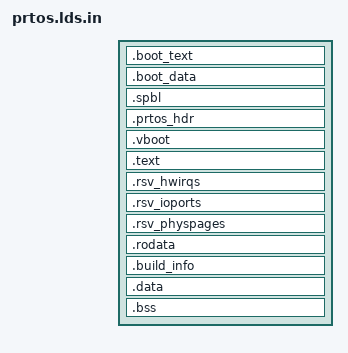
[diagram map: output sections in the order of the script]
/*
 * FILE: prtos.lds
 *
 * ld script to build the aarch64 version
 *
 * www.prtos.org
 */

#include <config.h>

OUTPUT_FORMAT("elf64-littleaarch64", "elf64-bigaarch64", "elf64-littleaarch64")
OUTPUT_ARCH("aarch64")
ENTRY(start)

PHYSOFFSET = - CONFIG_PRTOS_OFFSET + CONFIG_PRTOS_LOAD_ADDR;

SECTIONS
{
    . = CONFIG_PRTOS_OFFSET;
    _sprtos = .;

    _sboot = . + PHYSOFFSET;
    .boot_text ALIGN(0x1000) :  AT (ADDR (.boot_text) + PHYSOFFSET) {
        _stext = .;
        *(.boot.text)
        _etext = .;

        _idmap_start = .;
        *(.boot.text.header)
        *(.boot.text.idmap)
        *(.boot.rodata.idmap)
        *(.boot.data.idmap)
        _idmap_end = .;
    }
    .boot_data : AT (ADDR (.boot_data) + PHYSOFFSET) {
        *(.boot.data)
    }
    _eboot = . + PHYSOFFSET;


    .spbl ALIGN(0x1000) :  AT (ADDR (.spbl) + PHYSOFFSET) {
        _spbl = .;
        *(.pbl)
        _epbl = .;
    }
    .prtos_hdr ALIGN(0x1000) :  AT (ADDR (.prtos_hdr) + PHYSOFFSET) {
        *(.prtos_hdr)
    }

    
    .vboot ALIGN(0x1000) : AT (ADDR (.vboot) + PHYSOFFSET) {
        _svboot = .;
        *(.vboot.text)
        *(.vboot.data)
        _evboot = .;
    }

    .text ALIGN(0x1000) : AT (ADDR (.text) + PHYSOFFSET) {
        _sinittext = .;
        *(.text)
         _einittext = .;
        . = ALIGN(8);
        _sdevice = .;
        *(.dev.info)
        _edevice = .;
    }

    .rsv_hwirqs ALIGN(8) : {
        rsv_hw_irqs = .;
        *(.rsv_hwirqs)
        end_rsv_hw_irqs = .;
    }

    .rsv_ioports ALIGN(8) : {
        rsv_io_ports = .;
        *(.rsv_ioports)
        end_rsv_io_ports = .;
    }

    .rsv_physpages ALIGN(8) : {
        rsv_phys_pages = .;
        *(.rsv_physpages)
        end_rsv_phys_pages = .;
    }

    .rodata ALIGN(0x1000) : AT (ADDR (.rodata) + PHYSOFFSET) {
        _srodata = .;
        hypercalls_table = .;
        *(.hypercallstab)
        hypercall_flags_table = .;
        *(.hypercallflagstab)

        . = ALIGN(8);
        exception_table = .;
        *(.exptable)
        LONG(0);
        LONG(0);

        . = ALIGN(8);
        __gp_ex_table = .;
        *(.gp_ex_tab)
        LONG(0);
        
        . = ALIGN(8);
        kdev_table = .;
        *(.kdevtab)
        LONG(0);
        . = ALIGN(8);

        kdev_setup = .;
        *(.kdevsetup)
        LONG(0);
        
        . = ALIGN(8);
        object_setup_table = .;
        *(.objsetuptab)
        LONG(0);
        
        . = ALIGN(8);
        *(.rodata)
        *(.rodata.*)
      _erodata = .;
    }
    
    .build_info ALIGN(8) :  AT (ADDR (.build_info) + PHYSOFFSET) {
        build_info = .;
        *(.kbuild_info)
        *(.build_info)
        BYTE(0);
    }

    . = ALIGN((1 << (7)));
    .data ALIGN(8) :  AT (ADDR (.data) + PHYSOFFSET) {
        _sdata = .;
        *(.data.page_aligned)
        . = ALIGN(8);
        *(.vboot.data)
        *(.data)

        _edata = .;
        sys_reset_counter = .;
        LONG(0);
        reset_status_init = .;
        LONG(0);
        _cpdata = .;
        LONG(0);

       . = ALIGN((1 << 12));
       *(.init.rodata)
       *(.init.rodata.*)
       . = ALIGN((1 << 3));
       __setup_start = .;
       *(.init.setup)
       __setup_end = .;
       __initcall_start = .;
       *(.initcallpresmp.init)
       __presmp_initcall_end = .;
       *(.initcall1.init)
       __initcall_end = .;
       . = ALIGN(4);
       __alt_instructions = .;
       *(.altinstructions)
       __alt_instructions_end = .;
      
       *(.init.data)
       *(.init.data.rel)
       *(.init.data.rel.*)
       . = ALIGN(8);
       __ctors_start = .;
       *(.ctors)
       *(.init_array)
       *(SORT(.init_array.*))
       __ctors_end = .;



    . = ALIGN((1 << 12));
      __ro_after_init_start = .;
      *(.data.ro_after_init)
      . = ALIGN((1 << 12));
      __ro_after_init_end = .;

       __start___ex_table = .;
       *(.ex_table)
       __stop___ex_table = .;
       __start___pre_ex_table = .;
       *(.ex_table.pre)
       __stop___pre_ex_table = .;
       *(.data.read_mostly)
    . = ALIGN((1 << (7)));
       *(.data.page_aligned)
       . = ALIGN(8);
       __start_schedulers_array = .;
       *(.data.schedulers)
       __end_schedulers_array = .;
       . = ALIGN((1 << 3)); __paramhypfs_start = .; *(.data.paramhypfs) 
	   __paramhypfs_end = .;

      _splatform = .;
      *(.arch.info)
      _eplatform = .;


    }

    .bss ALIGN(8) :  AT (ADDR (.bss) + PHYSOFFSET) {
        _sbss = .;
        *(COMMON)

        . = ALIGN(((1 << 12) << 3));
        __init_end = .;
       __bss_start = .;
       *(.bss.stack_aligned)
       *(.bss.page_aligned)
       . = ALIGN(4K);
       __per_cpu_start = .;
       *(.bss.percpu.page_aligned)
       *(.bss.percpu)
       . = ALIGN(128);
       *(.bss.percpu.read_mostly)
       . = ALIGN(128);
       __per_cpu_data_end = .;
       *(.bss .bss.*)
       . = ALIGN(8);
       __bss_end = .;

        _ebss = .; 
        . = ALIGN(8);
        _scdata = .;
        . = . + SIZEOF(.data);
        _ecdata = .;
        *(.bss.noinit)
    }

    . = ALIGN(4K);
    prtos_conf_table = .;
    phys_prtos_conf_table = . + PHYSOFFSET;
    _eprtos = .;

    /DISCARD/ : {
        *(.note)
        *(.comment*)
    }

}
